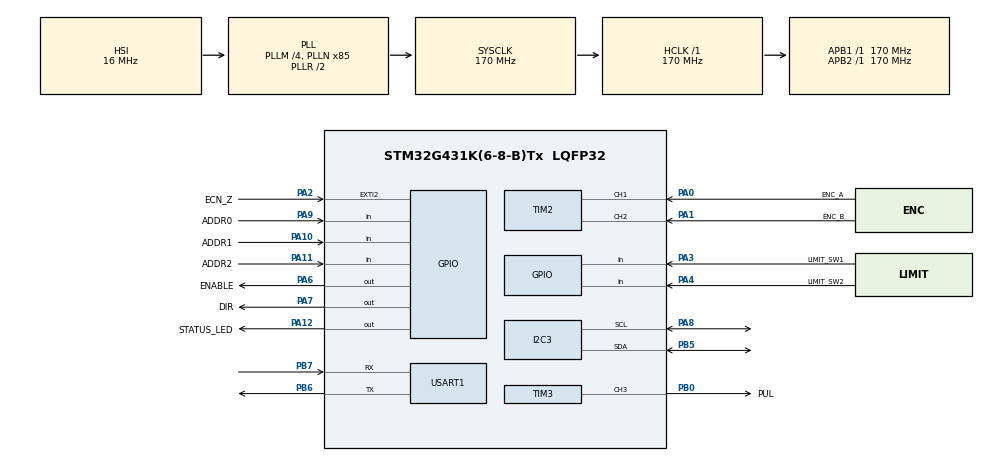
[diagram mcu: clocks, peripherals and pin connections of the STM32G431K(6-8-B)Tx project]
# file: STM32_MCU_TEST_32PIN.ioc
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I2C3.Timing=0x40B285C2
Mcu.Family=STM32G4
Mcu.Name=STM32G431K(6-8-B)Tx
Mcu.Package=LQFP32
NVIC.EXTI2_IRQn=true\:0\:0\:false\:false\:true\:true\:true\:true
NVIC.PriorityGroup=NVIC_PRIORITYGROUP_4
NVIC.TIM2_IRQn=true\:0\:0\:false\:false\:true\:true\:true\:true
NVIC.TIM6_DAC_IRQn=true\:0\:0\:false\:false\:true\:true\:true\:true
NVIC.USART1_IRQn=true\:0\:0\:false\:false\:true\:true\:true\:true
PA0.GPIO_Label=ENC_A
PA0.Signal=S_TIM2_CH1
PA1.GPIO_Label=ENC_B
PA1.Signal=S_TIM2_CH2
PA10.GPIO_Label=ADDR1
PA10.GPIO_PuPd=GPIO_PULLUP
PA10.Signal=GPIO_Input
PA11.GPIO_Label=ADDR2
PA11.GPIO_PuPd=GPIO_PULLUP
PA11.Signal=GPIO_Input
PA12.GPIO_Label=STATUS_LED
PA12.Signal=GPIO_Output
PA13.Mode=Trace_Asynchronous_SW
PA13.Signal=SYS_JTMS-SWDIO
PA14.Mode=Trace_Asynchronous_SW
PA14.Signal=SYS_JTCK-SWCLK
PA2.GPIO_Label=ECN_Z
PA2.GPIO_ModeDefaultEXTI=GPIO_MODE_IT_RISING
PA2.GPIO_PuPd=GPIO_PULLUP
PA2.Signal=GPXTI2
PA3.GPIO_Label=LIMIT_SW1
PA3.GPIO_PuPd=GPIO_PULLUP
PA3.Signal=GPIO_Input
PA4.GPIO_Label=LIMIT_SW2
PA4.GPIO_PuPd=GPIO_PULLUP
PA4.Signal=GPIO_Input
PA6.GPIO_Label=ENABLE
PA6.Signal=GPIO_Output
PA7.GPIO_Label=DIR
PA7.Signal=GPIO_Output
PA8.Mode=I2C
PA8.Signal=I2C3_SCL
PA9.GPIO_Label=ADDR0
PA9.GPIO_PuPd=GPIO_PULLUP
PA9.Signal=GPIO_Input
PB0.GPIO_Label=PUL
PB0.Signal=S_TIM3_CH3
PB3.Mode=Trace_Asynchronous_SW
PB3.Signal=SYS_JTDO-SWO
PB5.Mode=I2C
PB5.Signal=I2C3_SDA
PB6.Mode=Asynchronous
PB6.Signal=USART1_TX
PB7.Mode=Asynchronous
PB7.Signal=USART1_RX
PF0-OSC_IN.Mode=HSE-External-Oscillator
PF0-OSC_IN.Signal=RCC_OSC_IN
PF1-OSC_OUT.Mode=HSE-External-Oscillator
PF1-OSC_OUT.Signal=RCC_OSC_OUT
ProjectManager.HeapSize=0x200
ProjectManager.StackSize=0x400
ProjectManager.TargetToolchain=Makefile
RCC.ADC12Freq_Value=170000000
RCC.AHBFreq_Value=170000000
RCC.APB1Freq_Value=170000000
RCC.APB1TimFreq_Value=170000000
RCC.APB2Freq_Value=170000000
RCC.APB2TimFreq_Value=170000000
RCC.CortexFreq_Value=170000000
RCC.EXTERNAL_CLOCK_VALUE=12288000
RCC.HCLKFreq_Value=170000000
RCC.HSE_VALUE=8000000
RCC.HSI48_VALUE=48000000
RCC.HSI_VALUE=16000000
RCC.LSE_VALUE=32768
RCC.PLLM=RCC_PLLM_DIV4
RCC.PLLN=85
RCC.SYSCLKFreq_VALUE=170000000
RCC.SYSCLKSource=RCC_SYSCLKSOURCE_PLLCLK
RCC.USBFreq_Value=170000000
RCC.VCOOutputFreq_Value=340000000
SH.S_TIM2_CH1.0=TIM2_CH1,Encoder_Interface
SH.S_TIM2_CH2.0=TIM2_CH2,Encoder_Interface
SH.S_TIM3_CH3.0=TIM3_CH3,PWM Generation3 CH3
TIM2.AutoReloadPreload=TIM_AUTORELOAD_PRELOAD_ENABLE
TIM3.AutoReloadPreload=TIM_AUTORELOAD_PRELOAD_ENABLE
TIM3.Channel-PWM\ Generation3\ CH3=TIM_CHANNEL_3
TIM3.PeriodNoDither=999
TIM3.Prescaler=16
TIM6.AutoReloadPreload=TIM_AUTORELOAD_PRELOAD_ENABLE
TIM6.PeriodNoDither=999
TIM6.Prescaler=169
USART1.VirtualMode-Asynchronous=VM_ASYNC
VP_SYS_VS_DBSignals.Mode=DisableDeadBatterySignals
VP_TIM6_VS_ClockSourceINT.Mode=Enable_Timer
board=custom

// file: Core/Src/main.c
/* USER CODE BEGIN Header */
/**
  ******************************************************************************
  * @file           : main.c
  * @brief          : Main program body
  ******************************************************************************
  * @attention
  *
  * Copyright (c) 2025 STMicroelectronics.
  * All rights reserved.
  *
  * This software is licensed under terms that can be found in the LICENSE file
  * in the root directory of this software component.
  * If no LICENSE file comes with this software, it is provided AS-IS.
  *
  ******************************************************************************
  */
/* USER CODE END Header */
#include "main.h"

/* USER CODE BEGIN Includes */
#include "app.h"
/* USER CODE END Includes */

I2C_HandleTypeDef hi2c3;

TIM_HandleTypeDef htim2;
TIM_HandleTypeDef htim3;
TIM_HandleTypeDef htim6;

UART_HandleTypeDef huart1;

void SystemClock_Config(void);
static void MX_GPIO_Init(void);
static void MX_I2C3_Init(void);
static void MX_TIM2_Init(void);
static void MX_TIM3_Init(void);
static void MX_TIM6_Init(void);
static void MX_USART1_UART_Init(void);

int main(void)
{

  /* MCU Configuration--------------------------------------------------------*/

  /* Reset of all peripherals, Initializes the Flash interface and the Systick. */
  HAL_Init();

  /* Configure the system clock */
  SystemClock_Config();

  /* Initialize all configured peripherals */
  MX_GPIO_Init();
  MX_I2C3_Init();
  MX_TIM2_Init();
  MX_TIM3_Init();
  MX_TIM6_Init();
  MX_USART1_UART_Init();
  /* USER CODE BEGIN 2 */
  App_Init();
  /* USER CODE END 2 */

  /* Infinite loop */
  /* USER CODE BEGIN WHILE */
  while (1)
  {
    App_Run();
    /* USER CODE END WHILE */

  }
}

void SystemClock_Config(void)
{
  RCC_OscInitTypeDef RCC_OscInitStruct = {0};
  RCC_ClkInitTypeDef RCC_ClkInitStruct = {0};

  /** Configure the main internal regulator output voltage
  */
  HAL_PWREx_ControlVoltageScaling(PWR_REGULATOR_VOLTAGE_SCALE1_BOOST);

  /** Initializes the RCC Oscillators according to the specified parameters
  * in the RCC_OscInitTypeDef structure.
  */
  RCC_OscInitStruct.OscillatorType = RCC_OSCILLATORTYPE_HSI;
  RCC_OscInitStruct.HSIState = RCC_HSI_ON;
  RCC_OscInitStruct.HSICalibrationValue = RCC_HSICALIBRATION_DEFAULT;
  RCC_OscInitStruct.PLL.PLLState = RCC_PLL_ON;
  RCC_OscInitStruct.PLL.PLLSource = RCC_PLLSOURCE_HSI;
  RCC_OscInitStruct.PLL.PLLM = RCC_PLLM_DIV4;
  RCC_OscInitStruct.PLL.PLLN = 85;
  RCC_OscInitStruct.PLL.PLLP = RCC_PLLP_DIV2;
  RCC_OscInitStruct.PLL.PLLQ = RCC_PLLQ_DIV2;
  RCC_OscInitStruct.PLL.PLLR = RCC_PLLR_DIV2;
  if (HAL_RCC_OscConfig(&RCC_OscInitStruct) != HAL_OK)
  {
    Error_Handler();
  }

  /** Initializes the CPU, AHB and APB buses clocks
  */
  RCC_ClkInitStruct.ClockType = RCC_CLOCKTYPE_HCLK|RCC_CLOCKTYPE_SYSCLK
                              |RCC_CLOCKTYPE_PCLK1|RCC_CLOCKTYPE_PCLK2;
  RCC_ClkInitStruct.SYSCLKSource = RCC_SYSCLKSOURCE_PLLCLK;
  RCC_ClkInitStruct.AHBCLKDivider = RCC_SYSCLK_DIV1;
  RCC_ClkInitStruct.APB1CLKDivider = RCC_HCLK_DIV1;
  RCC_ClkInitStruct.APB2CLKDivider = RCC_HCLK_DIV1;

  if (HAL_RCC_ClockConfig(&RCC_ClkInitStruct, FLASH_LATENCY_4) != HAL_OK)
  {
    Error_Handler();
  }
}

static void MX_I2C3_Init(void)
{

  hi2c3.Instance = I2C3;
  hi2c3.Init.Timing = 0x40B285C2;
  hi2c3.Init.OwnAddress1 = 0;
  hi2c3.Init.AddressingMode = I2C_ADDRESSINGMODE_7BIT;
  hi2c3.Init.DualAddressMode = I2C_DUALADDRESS_DISABLE;
  hi2c3.Init.OwnAddress2 = 0;
  hi2c3.Init.OwnAddress2Masks = I2C_OA2_NOMASK;
  hi2c3.Init.GeneralCallMode = I2C_GENERALCALL_DISABLE;
  hi2c3.Init.NoStretchMode = I2C_NOSTRETCH_DISABLE;
  if (HAL_I2C_Init(&hi2c3) != HAL_OK)
  {
    Error_Handler();
  }

  /** Configure Analogue filter
  */
  if (HAL_I2CEx_ConfigAnalogFilter(&hi2c3, I2C_ANALOGFILTER_ENABLE) != HAL_OK)
  {
    Error_Handler();
  }

  /** Configure Digital filter
  */
  if (HAL_I2CEx_ConfigDigitalFilter(&hi2c3, 0) != HAL_OK)
  {
    Error_Handler();
  }

}

static void MX_TIM2_Init(void)
{

  TIM_Encoder_InitTypeDef sConfig = {0};
  TIM_MasterConfigTypeDef sMasterConfig = {0};

  htim2.Instance = TIM2;
  htim2.Init.Prescaler = 0;
  htim2.Init.CounterMode = TIM_COUNTERMODE_UP;
  htim2.Init.Period = 4294967295;
  htim2.Init.ClockDivision = TIM_CLOCKDIVISION_DIV1;
  htim2.Init.AutoReloadPreload = TIM_AUTORELOAD_PRELOAD_ENABLE;
  sConfig.EncoderMode = TIM_ENCODERMODE_TI1;
  sConfig.IC1Polarity = TIM_ICPOLARITY_RISING;
  sConfig.IC1Selection = TIM_ICSELECTION_DIRECTTI;
  sConfig.IC1Prescaler = TIM_ICPSC_DIV1;
  sConfig.IC1Filter = 0;
  sConfig.IC2Polarity = TIM_ICPOLARITY_RISING;
  sConfig.IC2Selection = TIM_ICSELECTION_DIRECTTI;
  sConfig.IC2Prescaler = TIM_ICPSC_DIV1;
  sConfig.IC2Filter = 0;
  if (HAL_TIM_Encoder_Init(&htim2, &sConfig) != HAL_OK)
  {
    Error_Handler();
  }
  sMasterConfig.MasterOutputTrigger = TIM_TRGO_RESET;
  sMasterConfig.MasterSlaveMode = TIM_MASTERSLAVEMODE_DISABLE;
  if (HAL_TIMEx_MasterConfigSynchronization(&htim2, &sMasterConfig) != HAL_OK)
  {
    Error_Handler();
  }

}

static void MX_TIM3_Init(void)
{

  TIM_MasterConfigTypeDef sMasterConfig = {0};
  TIM_OC_InitTypeDef sConfigOC = {0};

  htim3.Instance = TIM3;
  htim3.Init.Prescaler = 16;
  htim3.Init.CounterMode = TIM_COUNTERMODE_UP;
  htim3.Init.Period = 999;
  htim3.Init.ClockDivision = TIM_CLOCKDIVISION_DIV1;
  htim3.Init.AutoReloadPreload = TIM_AUTORELOAD_PRELOAD_ENABLE;
  if (HAL_TIM_PWM_Init(&htim3) != HAL_OK)
  {
    Error_Handler();
  }
  sMasterConfig.MasterOutputTrigger = TIM_TRGO_RESET;
  sMasterConfig.MasterSlaveMode = TIM_MASTERSLAVEMODE_DISABLE;
  if (HAL_TIMEx_MasterConfigSynchronization(&htim3, &sMasterConfig) != HAL_OK)
  {
    Error_Handler();
  }
  sConfigOC.OCMode = TIM_OCMODE_PWM1;
  sConfigOC.Pulse = 0;
  sConfigOC.OCPolarity = TIM_OCPOLARITY_HIGH;
  sConfigOC.OCFastMode = TIM_OCFAST_DISABLE;
  if (HAL_TIM_PWM_ConfigChannel(&htim3, &sConfigOC, TIM_CHANNEL_3) != HAL_OK)
  {
    Error_Handler();
  }
  HAL_TIM_MspPostInit(&htim3);

}

static void MX_TIM6_Init(void)
{

  TIM_MasterConfigTypeDef sMasterConfig = {0};

  htim6.Instance = TIM6;
  htim6.Init.Prescaler = 169;
  htim6.Init.CounterMode = TIM_COUNTERMODE_UP;
  htim6.Init.Period = 999;
  htim6.Init.AutoReloadPreload = TIM_AUTORELOAD_PRELOAD_ENABLE;
  if (HAL_TIM_Base_Init(&htim6) != HAL_OK)
  {
    Error_Handler();
  }
  sMasterConfig.MasterOutputTrigger = TIM_TRGO_RESET;
  sMasterConfig.MasterSlaveMode = TIM_MASTERSLAVEMODE_DISABLE;
  if (HAL_TIMEx_MasterConfigSynchronization(&htim6, &sMasterConfig) != HAL_OK)
  {
    Error_Handler();
  }

}

static void MX_USART1_UART_Init(void)
{

  huart1.Instance = USART1;
  huart1.Init.BaudRate = 115200;
  huart1.Init.WordLength = UART_WORDLENGTH_8B;
  huart1.Init.StopBits = UART_STOPBITS_1;
  huart1.Init.Parity = UART_PARITY_NONE;
  huart1.Init.Mode = UART_MODE_TX_RX;
  huart1.Init.HwFlowCtl = UART_HWCONTROL_NONE;
  huart1.Init.OverSampling = UART_OVERSAMPLING_16;
  huart1.Init.OneBitSampling = UART_ONE_BIT_SAMPLE_DISABLE;
  huart1.Init.ClockPrescaler = UART_PRESCALER_DIV1;
  huart1.AdvancedInit.AdvFeatureInit = UART_ADVFEATURE_NO_INIT;
  if (HAL_UART_Init(&huart1) != HAL_OK)
  {
    Error_Handler();
  }
  if (HAL_UARTEx_SetTxFifoThreshold(&huart1, UART_TXFIFO_THRESHOLD_1_8) != HAL_OK)
  {
    Error_Handler();
  }
  if (HAL_UARTEx_SetRxFifoThreshold(&huart1, UART_RXFIFO_THRESHOLD_1_8) != HAL_OK)
  {
    Error_Handler();
  }
  if (HAL_UARTEx_DisableFifoMode(&huart1) != HAL_OK)
  {
    Error_Handler();
  }

}

static void MX_GPIO_Init(void)
{
  GPIO_InitTypeDef GPIO_InitStruct = {0};

  /* GPIO Ports Clock Enable */
  __HAL_RCC_GPIOF_CLK_ENABLE();
  __HAL_RCC_GPIOA_CLK_ENABLE();
  __HAL_RCC_GPIOB_CLK_ENABLE();

  /*Configure GPIO pin Output Level */
  HAL_GPIO_WritePin(GPIOA, ENABLE_Pin|DIR_Pin|STATUS_LED_Pin, GPIO_PIN_RESET);

  /*Configure GPIO pin : ECN_Z_Pin */
  GPIO_InitStruct.Pin = ECN_Z_Pin;
  GPIO_InitStruct.Mode = GPIO_MODE_IT_RISING;
  GPIO_InitStruct.Pull = GPIO_PULLUP;
  HAL_GPIO_Init(ECN_Z_GPIO_Port, &GPIO_InitStruct);

  /*Configure GPIO pins : LIMIT_SW1_Pin LIMIT_SW2_Pin ADDR0_Pin ADDR1_Pin
                           ADDR2_Pin */
  GPIO_InitStruct.Pin = LIMIT_SW1_Pin|LIMIT_SW2_Pin|ADDR0_Pin|ADDR1_Pin
                          |ADDR2_Pin;
  GPIO_InitStruct.Mode = GPIO_MODE_INPUT;
  GPIO_InitStruct.Pull = GPIO_PULLUP;
  HAL_GPIO_Init(GPIOA, &GPIO_InitStruct);

  /*Configure GPIO pins : ENABLE_Pin DIR_Pin STATUS_LED_Pin */
  GPIO_InitStruct.Pin = ENABLE_Pin|DIR_Pin|STATUS_LED_Pin;
  GPIO_InitStruct.Mode = GPIO_MODE_OUTPUT_PP;
  GPIO_InitStruct.Pull = GPIO_NOPULL;
  GPIO_InitStruct.Speed = GPIO_SPEED_FREQ_LOW;
  HAL_GPIO_Init(GPIOA, &GPIO_InitStruct);

  /* EXTI interrupt init*/
  HAL_NVIC_SetPriority(EXTI2_IRQn, 0, 0);
  HAL_NVIC_EnableIRQ(EXTI2_IRQn);

}

/* USER CODE BEGIN 4 */
/**
 * @brief  UART RX complete — fires after each byte received.
 *         Routes byte into the ModBus frame assembler.
 */
void HAL_UART_RxCpltCallback(UART_HandleTypeDef *huart)
{
    if (huart->Instance == USART1) {
        /* s_mb.rx_byte is the byte just received (set up in App_Init) */
        //extern uint8_t _mb_rx_byte_extern;  /* See note below */
        ModBus_RxByteCallback(huart->pRxBuffPtr[-1]);
        /* Re-arm single-byte receive is handled inside ModBus_RxByteCallback */
    }
}

/*
 * NOTE on RX byte access:
 * The simplest approach is to declare the rx_byte field accessible.
 * In app.c the static struct has a field `rx_byte`. To avoid exposing
 * internals, add a tiny accessor in app.c:
 *
 *   uint8_t App_GetLastRxByte(void) { return s_mb.rx_byte; }
 *
 * Then call ModBus_RxByteCallback(App_GetLastRxByte()) here.
 *
 * OR: Declare rx_byte at file scope in app.c (not inside the struct)
 * so the HAL callback can reference it directly via extern.
 *
 * The cleanest approach: in app.c, change s_mb.rx_byte to:
 *   uint8_t g_mb_rx_byte;
 * (at file scope, not static), add `extern uint8_t g_mb_rx_byte;`
 * to app.h, and call ModBus_RxByteCallback(g_mb_rx_byte) here.
 */

/**
 * @brief  TIM period elapsed — fires every 1 ms from TIM6.
 *         Used for ModBus inter-frame gap detection and uptime.
 */
void HAL_TIM_PeriodElapsedCallback(TIM_HandleTypeDef *htim)
{
    if (htim->Instance == TIM6) {
        App_1msTickCallback();
    }
    /* Note: HAL_IncTick() is typically called here too if SysTick
     * is used — CubeMX usually places it here already. Keep it. */
}

/**
 * @brief  EXTI callback — fires on PA2 rising edge (encoder Z / index).
 */
void HAL_GPIO_EXTI_Callback(uint16_t GPIO_Pin)
{
    if (GPIO_Pin == GPIO_PIN_2) {
        Encoder_IndexCallback();
    }
}
/* USER CODE END 4 */

void Error_Handler(void)
{
  __disable_irq();
  while (1)
  {
  }
}
